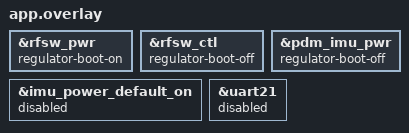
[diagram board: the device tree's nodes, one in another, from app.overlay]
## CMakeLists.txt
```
cmake_minimum_required(VERSION 3.20.0)
find_package(Zephyr REQUIRED HINTS $ENV{ZEPHYR_BASE})
project(nrf5_tag)

target_include_directories(app PRIVATE include)

target_sources(app PRIVATE
  src/main.c
  src/radio_zephyr.c
  src/radio_cycle.c
  src/beacon.c
)

option(BEACON_ALLOW_EXAMPLE_KEYS "Build with the nonfunctional example key" OFF)

set(BEACON_KEYS_C "${CMAKE_CURRENT_SOURCE_DIR}/src/keys.c" CACHE FILEPATH
    "Generated public key table compiled into the firmware")

if(EXISTS ${BEACON_KEYS_C})
  target_sources(app PRIVATE ${BEACON_KEYS_C})
elseif(BEACON_ALLOW_EXAMPLE_KEYS)
  target_sources(app PRIVATE src/keys.example.c)
else()
  message(FATAL_ERROR
    "Missing ${BEACON_KEYS_C}. Generate it with scripts/keys_csv_to_c.py, or set "
    "BEACON_ALLOW_EXAMPLE_KEYS=ON for a nonfunctional development build.")
endif()
```

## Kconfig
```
source "Kconfig.zephyr"

menu "nRF54L15 beacon"

config N_KEYS
	int "Number of beacon keys"
	default 50
	range 1 50

config REUSE_CYCLES
	int "Advertisement cycles before key reuse"
	default 1
	range 1 255

config ADVERTISE_WINDOW_S
	int "Advertisement window in seconds"
	default 1800
	range 1 65535
	help
	  Must cover at least one configured advertising interval. The upper
	  bound keeps the timeout conversion within the supported tick range.

config SLEEP_S
	int "Sleep interval in seconds"
	default 0
	range 0 65535

config ADV_INTERVAL_MS
	int "Advertisement interval in milliseconds"
	default 5000
	range 20 10240

config STATE_BYTE
	int "Initial state byte"
	default 0
	range 0 255

endmenu
```

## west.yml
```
manifest:
  version: "1.2"
  projects:
    - name: nrf
      url: https://github.com/nrfconnect/sdk-nrf.git
      revision: v3.2.1
      import: true
  self:
    path: nrf5-tag
```

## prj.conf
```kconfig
# Bluetooth broadcaster only. No connections, scanning, names, or scan response.
CONFIG_BT=y
CONFIG_BT_BROADCASTER=y
CONFIG_BT_ID_MAX=2
CONFIG_BT_EXT_ADV=n
CONFIG_BT_DEVICE_NAME=""

# Production beacon: no UART receiver or periodic log-processing wakeups.
# Add debug.conf explicitly when USB/SWD RTT diagnostics are needed.
CONFIG_SERIAL=n
CONFIG_CONSOLE=n
CONFIG_UART_CONSOLE=n
CONFIG_LOG=n
CONFIG_NCS_BOOT_BANNER=n
CONFIG_BOOT_BANNER=n
CONFIG_PRINTK=n
CONFIG_REBOOT=y

# This broadcaster uses static pools, not the libc post-image malloc arena.
CONFIG_COMMON_LIBC_MALLOC_ARENA_SIZE=0
CONFIG_RAM_POWER_DOWN_LIBRARY=y

# Keep the image small and avoid unused host features.
CONFIG_BT_SETTINGS=n
CONFIG_BT_OBSERVER=n
CONFIG_BT_CENTRAL=n
CONFIG_BT_PERIPHERAL=n
```

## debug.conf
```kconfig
# Development only: RTT over the onboard USB/SWD probe; no external UART needed.
# Drop normal logs when detached rather than blocking the radio thread.
CONFIG_USE_SEGGER_RTT=y
CONFIG_SEGGER_RTT_BUFFER_SIZE_UP=4096
CONFIG_CONSOLE=y
CONFIG_RTT_CONSOLE=y
CONFIG_PRINTK=y
CONFIG_NCS_BOOT_BANNER=y
CONFIG_LOG=y
CONFIG_LOG_MODE_DEFERRED=y
CONFIG_LOG_BACKEND_RTT=y
CONFIG_LOG_BACKEND_RTT_MODE_DROP=y
CONFIG_LOG_BACKEND_RTT_MESSAGE_SIZE=256
CONFIG_ASSERT=y
CONFIG_DEBUG_OPTIMIZATIONS=y
CONFIG_RAM_POWER_DOWN_LIBRARY=n
CONFIG_COMMON_LIBC_MALLOC_ARENA_SIZE=-1
```

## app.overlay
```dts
/* NCS v3.2.1 declares both controls active-high. Power the RF switch and
 * drive its select low for the onboard ceramic antenna (Seeed wiring).
 */
&rfsw_pwr {
	regulator-boot-on;
};

&rfsw_ctl {
	regulator-boot-off;
};

/* The beacon does not use the IMU/microphone supply. Explicitly drive it off,
 * including after resets where the enable pin may already be high.
 */
&pdm_imu_pwr {
	/delete-property/ regulator-boot-on;
	regulator-boot-off;
};

/* The board's GPIO hog shares the regulator enable pin. Keep one owner. */
&imu_power_default_on {
	status = "disabled";
};

/* UART20 remains available for debug.conf; UART21 is never used. */
&uart21 {
	status = "disabled";
};
```

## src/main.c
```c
#include "radio_zephyr.h"

#include <zephyr/sys/reboot.h>

#if defined(CONFIG_RAM_POWER_DOWN_LIBRARY)
#include <stdint.h>
#include <ram_pwrdn.h>
#include <zephyr/devicetree.h>
#include <zephyr/sys/util.h>

extern char _image_ram_end[];

BUILD_ASSERT(CONFIG_COMMON_LIBC_MALLOC_ARENA_SIZE == 0,
             "RAM power-down requires the post-image libc heap to be disabled");
BUILD_ASSERT(CONFIG_NRF_FORCE_RAM_ON_REBOOT,
             "RAM must be restored before a software reboot");
#endif

int main(void)
{
#if defined(CONFIG_RAM_POWER_DOWN_LIBRARY)
    /* Stay within CPUAPP RAM; the unused-RAM helper also reaches FLPR memory. */
    power_down_ram((uintptr_t)_image_ram_end,
                   DT_REG_ADDR(DT_CHOSEN(zephyr_sram)) +
                       DT_REG_SIZE(DT_CHOSEN(zephyr_sram)));
#endif
    if (radio_zephyr_run() != 0) {
        sys_reboot(SYS_REBOOT_COLD);
    }

    return 0;
}
```

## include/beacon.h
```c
#ifndef BEACON_H
#define BEACON_H

#include <stddef.h>
#include <stdint.h>

enum {
    BEACON_KEY_BYTES = 28,
    BEACON_ADDRESS_BYTES = 6,
    BEACON_MANUFACTURER_PAYLOAD_BYTES = 29,
    BEACON_AD_BYTES = 31
};

enum beacon_result {
    BEACON_OK = 0,
    BEACON_ERR_ARGUMENT = -1,
    BEACON_ERR_KEY_COUNT = -2,
    BEACON_ERR_REUSE_CYCLES = -3,
    BEACON_ERR_ADDRESS = -4
};

struct beacon_rotation_state {
    size_t key_index;
    uint32_t cycle;
};

int beacon_address_from_key(const uint8_t key[BEACON_KEY_BYTES],
                            uint8_t address[BEACON_ADDRESS_BYTES]);

int beacon_key_table_validate(
    const uint8_t (*keys)[BEACON_KEY_BYTES], size_t key_count,
    size_t configured_max);

int beacon_manufacturer_payload_from_key(
    const uint8_t key[BEACON_KEY_BYTES],
    uint8_t payload[BEACON_MANUFACTURER_PAYLOAD_BYTES], uint8_t state);

int beacon_ad_from_key(const uint8_t key[BEACON_KEY_BYTES],
                       uint8_t ad[BEACON_AD_BYTES], uint8_t state);

void beacon_rotation_init(struct beacon_rotation_state *rotation);

/*
 * Advances the persistent scheduler state after a use of key_index.
 * Starting at {0, 0}, reuse_cycles == 1 yields upstream-style uses of
 * index 0 at startup and index 1 after the first advance.
 */
int beacon_rotation_advance(struct beacon_rotation_state *rotation,
                            size_t key_count, uint32_t reuse_cycles);

#endif
```

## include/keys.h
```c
#ifndef KEYS_H
#define KEYS_H

#include <stddef.h>
#include <stdint.h>

#include "beacon.h"

extern const uint8_t beacon_keys[][BEACON_KEY_BYTES];
extern const size_t beacon_key_count;

#endif
```

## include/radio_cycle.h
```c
#ifndef RADIO_CYCLE_H
#define RADIO_CYCLE_H

#include <stddef.h>
#include <stdint.h>

#include "beacon.h"

struct radio_cycle_config {
    size_t key_count;
    uint32_t reuse_cycles;
    uint32_t advertise_seconds;
    uint32_t sleep_seconds;
    uint16_t interval_units;
};

struct radio_cycle_ops {
    int (*start)(void *context, size_t key_index, uint16_t interval_units);
    int (*stop)(void *context);
    int (*reset)(void *context, size_t next_key_index);
    void (*sleep)(void *context, uint32_t seconds);
    void *context;
};

int radio_cycle_run_once(struct beacon_rotation_state *rotation,
                         const struct radio_cycle_config *config,
                         const struct radio_cycle_ops *ops);

#endif
```

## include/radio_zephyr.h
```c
#ifndef RADIO_ZEPHYR_H
#define RADIO_ZEPHYR_H

int radio_zephyr_run(void);

#endif
```

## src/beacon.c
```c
#include "beacon.h"

#include <stdbool.h>
#include <string.h>

int beacon_address_from_key(const uint8_t key[BEACON_KEY_BYTES],
                            uint8_t address[BEACON_ADDRESS_BYTES])
{
    bool all_zero;
    bool all_one;
    size_t index;

    if (key == NULL || address == NULL) {
        return BEACON_ERR_ARGUMENT;
    }

    all_zero = (key[0] & 0x3fU) == 0U;
    all_one = (key[0] & 0x3fU) == 0x3fU;
    for (index = 1U; index < BEACON_ADDRESS_BYTES; ++index) {
        all_zero = all_zero && key[index] == 0U;
        all_one = all_one && key[index] == 0xffU;
    }
    if (all_zero || all_one) {
        return BEACON_ERR_ADDRESS;
    }

    address[0] = key[5];
    address[1] = key[4];
    address[2] = key[3];
    address[3] = key[2];
    address[4] = key[1];
    address[5] = (uint8_t)(key[0] | 0xc0U);
    return BEACON_OK;
}

int beacon_key_table_validate(
    const uint8_t (*keys)[BEACON_KEY_BYTES], size_t key_count,
    size_t configured_max)
{
    uint8_t address[BEACON_ADDRESS_BYTES];
    size_t index;
    int result;

    if (keys == NULL) {
        return BEACON_ERR_ARGUMENT;
    }
    if (key_count == 0U || key_count > configured_max) {
        return BEACON_ERR_KEY_COUNT;
    }

    for (index = 0U; index < key_count; ++index) {
        result = beacon_address_from_key(keys[index], address);
        if (result != BEACON_OK) {
            return result;
        }
    }

    return BEACON_OK;
}

int beacon_manufacturer_payload_from_key(
    const uint8_t key[BEACON_KEY_BYTES],
    uint8_t payload[BEACON_MANUFACTURER_PAYLOAD_BYTES], uint8_t state)
{
    if (key == NULL || payload == NULL) {
        return BEACON_ERR_ARGUMENT;
    }

    payload[0] = 0x4cU;
    payload[1] = 0x00U;
    payload[2] = 0x12U;
    payload[3] = 0x19U;
    payload[4] = state;
    memcpy(&payload[5], &key[6], 22U);
    payload[27] = (uint8_t)(key[0] >> 6U);
    payload[28] = 0x00U;
    return BEACON_OK;
}

int beacon_ad_from_key(const uint8_t key[BEACON_KEY_BYTES],
                       uint8_t ad[BEACON_AD_BYTES], uint8_t state)
{
    int result;

    if (ad == NULL) {
        return BEACON_ERR_ARGUMENT;
    }

    ad[0] = 0x1eU;
    ad[1] = 0xffU;
    result = beacon_manufacturer_payload_from_key(key, &ad[2], state);
    return result;
}

void beacon_rotation_init(struct beacon_rotation_state *rotation)
{
    if (rotation != NULL) {
        rotation->key_index = 0U;
        rotation->cycle = 0U;
    }
}

int beacon_rotation_advance(struct beacon_rotation_state *rotation,
                            size_t key_count, uint32_t reuse_cycles)
{
    if (rotation == NULL) {
        return BEACON_ERR_ARGUMENT;
    }
    if (key_count == 0U) {
        return BEACON_ERR_KEY_COUNT;
    }
    if (reuse_cycles == 0U) {
        return BEACON_ERR_REUSE_CYCLES;
    }

    rotation->key_index %= key_count;
    rotation->cycle += 1U;
    if (rotation->cycle >= reuse_cycles) {
        rotation->cycle = 0U;
        rotation->key_index = (rotation->key_index + 1U) % key_count;
    }
    return BEACON_OK;
}
```

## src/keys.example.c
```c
#include <stddef.h>
#include <stdint.h>

#include "beacon.h"
#include "keys.h"

const uint8_t beacon_keys[][BEACON_KEY_BYTES] = {
    /* P-224 generator X-coordinate; valid RF fixture without a backend key. */
    {
        0xb7, 0x0e, 0x0c, 0xbd, 0x6b, 0xb4, 0xbf,
        0x7f, 0x32, 0x13, 0x90, 0xb9, 0x4a, 0x03,
        0xc1, 0xd3, 0x56, 0xc2, 0x11, 0x22, 0x34,
        0x32, 0x80, 0xd6, 0x11, 0x5c, 0x1d, 0x21,
    },
};

const size_t beacon_key_count = sizeof(beacon_keys) / sizeof(beacon_keys[0]);
```

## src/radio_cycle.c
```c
#include "radio_cycle.h"

#include <errno.h>

int radio_cycle_run_once(struct beacon_rotation_state *rotation,
                         const struct radio_cycle_config *config,
                         const struct radio_cycle_ops *ops)
{
    int error;

    if (rotation == NULL || config == NULL || ops == NULL ||
        ops->start == NULL || ops->stop == NULL || ops->reset == NULL ||
        ops->sleep == NULL || config->key_count == 0U ||
        config->reuse_cycles == 0U || config->interval_units == 0U ||
        config->advertise_seconds == 0U ||
        rotation->key_index >= config->key_count) {
        return -EINVAL;
    }

    error = ops->start(ops->context, rotation->key_index,
                       config->interval_units);
    if (error != 0) {
        return error;
    }

    ops->sleep(ops->context, config->advertise_seconds);

    error = ops->stop(ops->context);
    if (error != 0) {
        (void)ops->stop(ops->context);
        return error;
    }

    error = beacon_rotation_advance(rotation, config->key_count,
                                    config->reuse_cycles);
    if (error != BEACON_OK) {
        return error;
    }

    error = ops->reset(ops->context, rotation->key_index);
    if (error != 0) {
        return error;
    }

    ops->sleep(ops->context, config->sleep_seconds);
    return 0;
}
```

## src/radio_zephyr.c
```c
#include "radio_zephyr.h"

#include <errno.h>
#include <stdint.h>
#include <string.h>

#include <zephyr/bluetooth/bluetooth.h>
#include <zephyr/kernel.h>
#include <zephyr/logging/log.h>
#include <zephyr/sys/util.h>

#include "beacon.h"
#include "keys.h"
#include "radio_cycle.h"

LOG_MODULE_REGISTER(radio_zephyr);

#define RADIO_DEDICATED_ID 1U
#define RADIO_ADV_INTERVAL_MIN 0x0020U
#define RADIO_ADV_INTERVAL_MAX 0x4000U
#define RADIO_ADV_INTERVAL_UNITS \
    ((uint16_t)(((uint64_t)CONFIG_ADV_INTERVAL_MS * 8U) / 5U))

BUILD_ASSERT(CONFIG_ADV_INTERVAL_MS > 0,
             "CONFIG_ADV_INTERVAL_MS must be positive");
BUILD_ASSERT((CONFIG_ADV_INTERVAL_MS % 5U) == 0U,
             "CONFIG_ADV_INTERVAL_MS must be a multiple of 5");
BUILD_ASSERT(((uint64_t)CONFIG_ADV_INTERVAL_MS * 8U) / 5U >=
                 RADIO_ADV_INTERVAL_MIN,
             "CONFIG_ADV_INTERVAL_MS is below the legacy advertising minimum");
BUILD_ASSERT(((uint64_t)CONFIG_ADV_INTERVAL_MS * 8U) / 5U <=
                 RADIO_ADV_INTERVAL_MAX,
             "CONFIG_ADV_INTERVAL_MS exceeds the legacy advertising maximum");
BUILD_ASSERT(CONFIG_ADVERTISE_WINDOW_S > 0 &&
                 CONFIG_ADVERTISE_WINDOW_S <= 65535,
             "CONFIG_ADVERTISE_WINDOW_S must be between 1 and 65535");
BUILD_ASSERT(CONFIG_SLEEP_S >= 0 && CONFIG_SLEEP_S <= 65535,
             "CONFIG_SLEEP_S must be between 0 and 65535");
BUILD_ASSERT((uint64_t)CONFIG_ADVERTISE_WINDOW_S * 1000U >=
                 CONFIG_ADV_INTERVAL_MS,
             "Advertisement window must cover at least one interval");

static int identity_address_from_key(
    const uint8_t key[BEACON_KEY_BYTES], bt_addr_le_t *address)
{
    int error;

    address->type = BT_ADDR_LE_RANDOM;
    error = beacon_address_from_key(key, address->a.val);
    if (error != BEACON_OK) {
        LOG_ERR("Could not derive identity address: %d", error);
        return -EINVAL;
    }

    return 0;
}

struct radio_zephyr_context {
    uint8_t dedicated_id;
    bt_addr_le_t identity_address;
};

static int reset_identity(struct radio_zephyr_context *radio,
                          const uint8_t key[BEACON_KEY_BYTES])
{
    bt_addr_le_t address;
    int error;

    error = identity_address_from_key(key, &address);
    if (error != 0) {
        return error;
    }

    if (address.type == radio->identity_address.type &&
        memcmp(address.a.val, radio->identity_address.a.val,
               sizeof(address.a.val)) == 0) {
        return 0;
    }

    error = bt_id_reset(radio->dedicated_id, &address, NULL);
    if (error < 0) {
        LOG_ERR("Could not reset identity %u: %d",
                (unsigned int)radio->dedicated_id,
                error);
        return error;
    }

    radio->identity_address = address;
    return 0;
}

static int start_advertising(void *context, size_t key_index,
                             uint16_t interval_units)
{
    const struct radio_zephyr_context *radio = context;
    uint8_t payload[BEACON_MANUFACTURER_PAYLOAD_BYTES];
    const struct bt_data ad[] = {
        BT_DATA(BT_DATA_MANUFACTURER_DATA, payload, sizeof(payload)),
    };
    const struct bt_le_adv_param parameters = {
        .id = radio->dedicated_id,
        .options = BT_LE_ADV_OPT_USE_IDENTITY,
        .interval_min = interval_units,
        .interval_max = interval_units,
    };
    int error;

    error = beacon_manufacturer_payload_from_key(beacon_keys[key_index], payload,
                                                 CONFIG_STATE_BYTE);
    if (error != BEACON_OK) {
        LOG_ERR("Could not construct advertisement payload: %d", error);
        return -EINVAL;
    }

    error = bt_le_adv_start(&parameters, ad, ARRAY_SIZE(ad), NULL, 0U);
    if (error != 0) {
        LOG_ERR("Could not start advertising: %d", error);
        return error;
    }

    LOG_INF("Advertising key %u", (unsigned int)key_index);
    return 0;
}

static int stop_advertising(void *context)
{
    int error;

    (void)context;
    error = bt_le_adv_stop();
    if (error != 0) {
        LOG_ERR("Could not stop advertising: %d", error);
    }
    return error;
}

static int reset_advertising_identity(void *context, size_t next_key_index)
{
    struct radio_zephyr_context *radio = context;

    return reset_identity(radio, beacon_keys[next_key_index]);
}

static void sleep_seconds(void *context, uint32_t seconds)
{
    (void)context;
    k_sleep(K_SECONDS(seconds));
}

int radio_zephyr_run(void)
{
    struct beacon_rotation_state rotation;
    struct radio_zephyr_context radio;
    const struct radio_cycle_config config = {
        .key_count = beacon_key_count,
        .reuse_cycles = CONFIG_REUSE_CYCLES,
        .advertise_seconds = CONFIG_ADVERTISE_WINDOW_S,
        .sleep_seconds = CONFIG_SLEEP_S,
        .interval_units = RADIO_ADV_INTERVAL_UNITS,
    };
    const struct radio_cycle_ops ops = {
        .start = start_advertising,
        .stop = stop_advertising,
        .reset = reset_advertising_identity,
        .sleep = sleep_seconds,
        .context = &radio,
    };
    uint8_t dedicated_id;
    int error;

    error = beacon_key_table_validate(beacon_keys, beacon_key_count,
                                      CONFIG_N_KEYS);
    if (error != BEACON_OK) {
        LOG_ERR("Invalid beacon key table: %d", error);
        return -EINVAL;
    }

    beacon_rotation_init(&rotation);

    error = bt_enable(NULL);
    if (error != 0) {
        LOG_ERR("Bluetooth initialization failed: %d", error);
        return error;
    }

    bt_addr_le_t address;
    error = identity_address_from_key(beacon_keys[rotation.key_index], &address);
    if (error != 0) {
        return error;
    }

    error = bt_id_create(&address, NULL);
    if (error < 0) {
        LOG_ERR("Could not create dedicated identity: %d", error);
        return error;
    }

    dedicated_id = (uint8_t)error;
    if (dedicated_id != RADIO_DEDICATED_ID) {
        LOG_ERR("Dedicated identity is %u, expected %u", (unsigned int)dedicated_id,
                RADIO_DEDICATED_ID);
        return -EIO;
    }

    LOG_INF("Bluetooth enabled with dedicated identity %u",
            (unsigned int)dedicated_id);
    radio.dedicated_id = dedicated_id;
    radio.identity_address = address;

    for (;;) {
        error = radio_cycle_run_once(&rotation, &config, &ops);
        if (error != 0) {
            LOG_ERR("Radio lifecycle failed: %d", error);
            return error;
        }
    }
}
```
